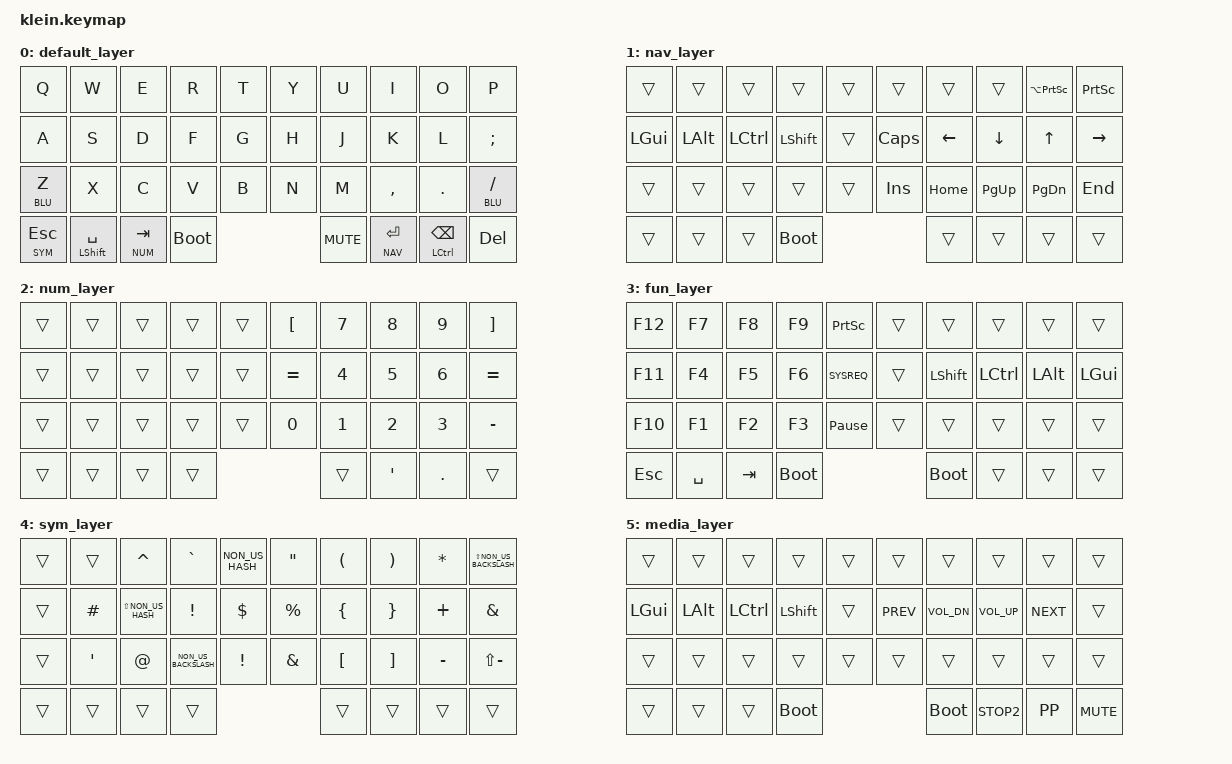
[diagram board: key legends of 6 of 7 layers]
/*
 * Copyright (c) 2020 The ZMK Contributors
 *
west build -d build/kleinleft -p -b seeeduino_xiao_ble -- -DSHIELD=klein_left
west build -d build/kleinright -p -b seeeduino_xiao_ble -- -DSHIELD=klein_right

west build -d build/kleinleft -p -b seeeduino_xiao_ble -- -DSHIELD=klein_left -DZMK_EXTRA_MODULES="/workspaces/zmk/app/cirque-input-module-main"
west build -d build/kleinright -p -b seeeduino_xiao_ble -- -DSHIELD=klein_right -DZMK_EXTRA_MODULES="/workspaces/zmk/app/cirque-input-module-main"

docker cp magical_haslett:/workspaces/zmk/app/build/kleinright/zephyr/zmk.uf2 ~/Desktop/kleinright.uf2

 * SPDX-License-Identifier: MIT
 */


#include <behaviors.dtsi>
#include <dt-bindings/zmk/keys.h>
#include <dt-bindings/zmk/bt.h>
#include <dt-bindings/zmk/outputs.h>
#include <dt-bindings/zmk/mouse.h>
#include <behaviors/mouse_keys.dtsi>

#define BASE 0
#define NAV  1
#define NUM  2
#define FUN  3
#define SYM  4
#define MEDIA  5
#define BLU 6

&mt {
    quick_tap_ms = <200>;
};

&lt {
    quick_tap_ms = <200>;
};

/ {
    keymap {
        compatible = "zmk,keymap";

        default_layer {
//          ------------------------------------------------------------------------------------------------------------
//          |  Q  |  W  |  E   |  R   |  T   |                                           |  Y   |  U    |  I    |  O   |   P   |
//          |  A  |  S  |  D   |  F   |  G   |                                           |  H   |  J    |  K    |  L   |   '   |
//          |  Z  |  X  |  C   |  V   |  B   |                                           |  N   |  M    |  ,    |  .   |   /   |
//                      | ESC  | SPC |  TAB | BOOTLOADER |                         | MUTE | RET | BKSP | DEL |

            bindings = <
&kp Q          &kp W          &kp E          &kp R          &kp T               &kp Y          &kp U          &kp I          &kp O          &kp P
&kp A          &kp S          &kp D          &kp F          &kp G               &kp H          &kp J          &kp K          &kp L          &kp SEMI
&lt BLU Z      &kp X          &kp C          &kp V          &kp B               &kp N          &kp M          &kp COMMA      &kp DOT        &lt BLU FSLH
&lt SYM ESC  &mt LSHFT SPACE  &lt NUM TAB    &bootloader                                       &kp K_MUTE     &lt NAV RET    &mt LCTRL BKSP   &kp DEL
            >;
        sensor-bindings = <&inc_dec_kp PG_UP PG_DN>;
        };

        nav_layer {

            bindings = <
&trans         &trans         &trans         &trans         &trans              &trans         &trans         &trans         &kp LA(PSCRN)  &kp PSCRN
&kp LGUI       &kp LALT       &kp LCTRL      &kp LSHFT      &trans              &kp CAPSLOCK   &kp LEFT       &kp DOWN       &kp UP         &kp RIGHT      
&trans         &trans         &trans         &trans         &trans              &kp INSERT     &kp HOME       &kp PG_UP      &kp PG_DN      &kp END
&trans         &trans         &trans         &bootloader                                       &trans         &trans         &trans         &trans
            >;
        sensor-bindings = <&inc_dec_kp PG_UP PG_DN>;
        };

        num_layer {
            
            bindings = <
&trans         &trans         &trans         &trans         &trans            &kp LBKT       &kp N7         &kp N8         &kp N9         &kp RBKT 
&trans         &trans         &trans         &trans         &trans            &kp EQUAL      &kp N4         &kp N5         &kp N6         &kp EQUAL
&trans         &trans         &trans         &trans         &trans            &kp N0         &kp N1         &kp N2         &kp N3         &kp MINUS
&trans         &trans         &trans         &trans                           &trans         &kp SQT        &kp DOT        &trans
            >;
        sensor-bindings = <&inc_dec_kp PG_UP PG_DN>;
        };

        fun_layer {
            
            bindings = <
&kp F12        &kp F7         &kp F8         &kp F9         &kp PSCRN           &trans         &trans         &trans         &trans         &trans
&kp F11        &kp F4         &kp F5         &kp F6         &kp SYSREQ          &trans         &kp LSHFT      &kp LCTRL      &kp LALT       &kp LGUI
&kp F10        &kp F1         &kp F2         &kp F3         &kp PAUSE_BREAK     &trans         &trans         &trans         &trans         &trans
&kp ESC        &kp SPACE      &kp TAB        &bootloader                                       &bootloader    &trans         &trans         &trans
            >;
        sensor-bindings = <&inc_dec_kp PG_UP PG_DN>;
        };

        sym_layer {
            
            bindings = <
&trans   &trans     &kp CARET               &kp GRAVE               &kp NON_US_HASH &kp DQT         &kp LPAR       &kp RPAR       &kp ASTERISK  &kp LS(NON_US_BACKSLASH)
&trans   &kp POUND  &kp LS(NON_US_HASH)     &kp EXCL                &kp DOLLAR      &kp PERCENT     &kp LBRC       &kp RBRC       &kp PLUS      &kp AMPS
&trans   &kp SQT    &kp AT                  &kp NON_US_BACKSLASH    &kp EXCL        &kp AMPS        &kp LBKT       &kp RBKT       &kp MINUS     &kp LS(MINUS)
&trans   &trans     &trans                  &trans                                                 &trans          &trans         &trans        &trans
            >;
        sensor-bindings = <&inc_dec_kp PG_UP PG_DN>;
        };

        media_layer {
            
            bindings = <
&trans         &trans         &trans         &trans         &trans              &trans         &trans         &trans         &trans         &trans
&kp LGUI       &kp LALT       &kp LCTRL      &kp LSHFT      &trans              &kp K_PREV     &kp K_VOL_DN   &kp K_VOL_UP   &kp K_NEXT     &trans
&trans         &trans         &trans         &trans         &trans              &trans         &trans         &trans         &trans         &trans
&trans         &trans         &trans         &bootloader                                       &bootloader    &kp K_STOP2    &kp K_PP       &kp K_MUTE
            >;
        sensor-bindings = <&inc_dec_kp PG_UP PG_DN>;
        };

        blu_layer {
            
            bindings = <
&bootloader    &trans         &trans         &trans         &bt BT_CLR          &bt BT_CLR     &trans         &trans         &trans         &bootloader
&trans         &bt BT_SEL 3   &bt BT_SEL 4   &trans         &trans              &trans         &bt BT_PRV     &bt BT_NXT     &trans         &trans
&trans         &bt BT_SEL 0   &bt BT_SEL 1   &bt BT_SEL 2   &trans              &trans         &trans         &trans         &trans         &trans
&trans         &trans         &trans         &trans         &trans                             &trans         &trans         &trans         &trans
            >;
        sensor-bindings = <&inc_dec_kp PG_UP PG_DN>;
        };
    };
};
 
